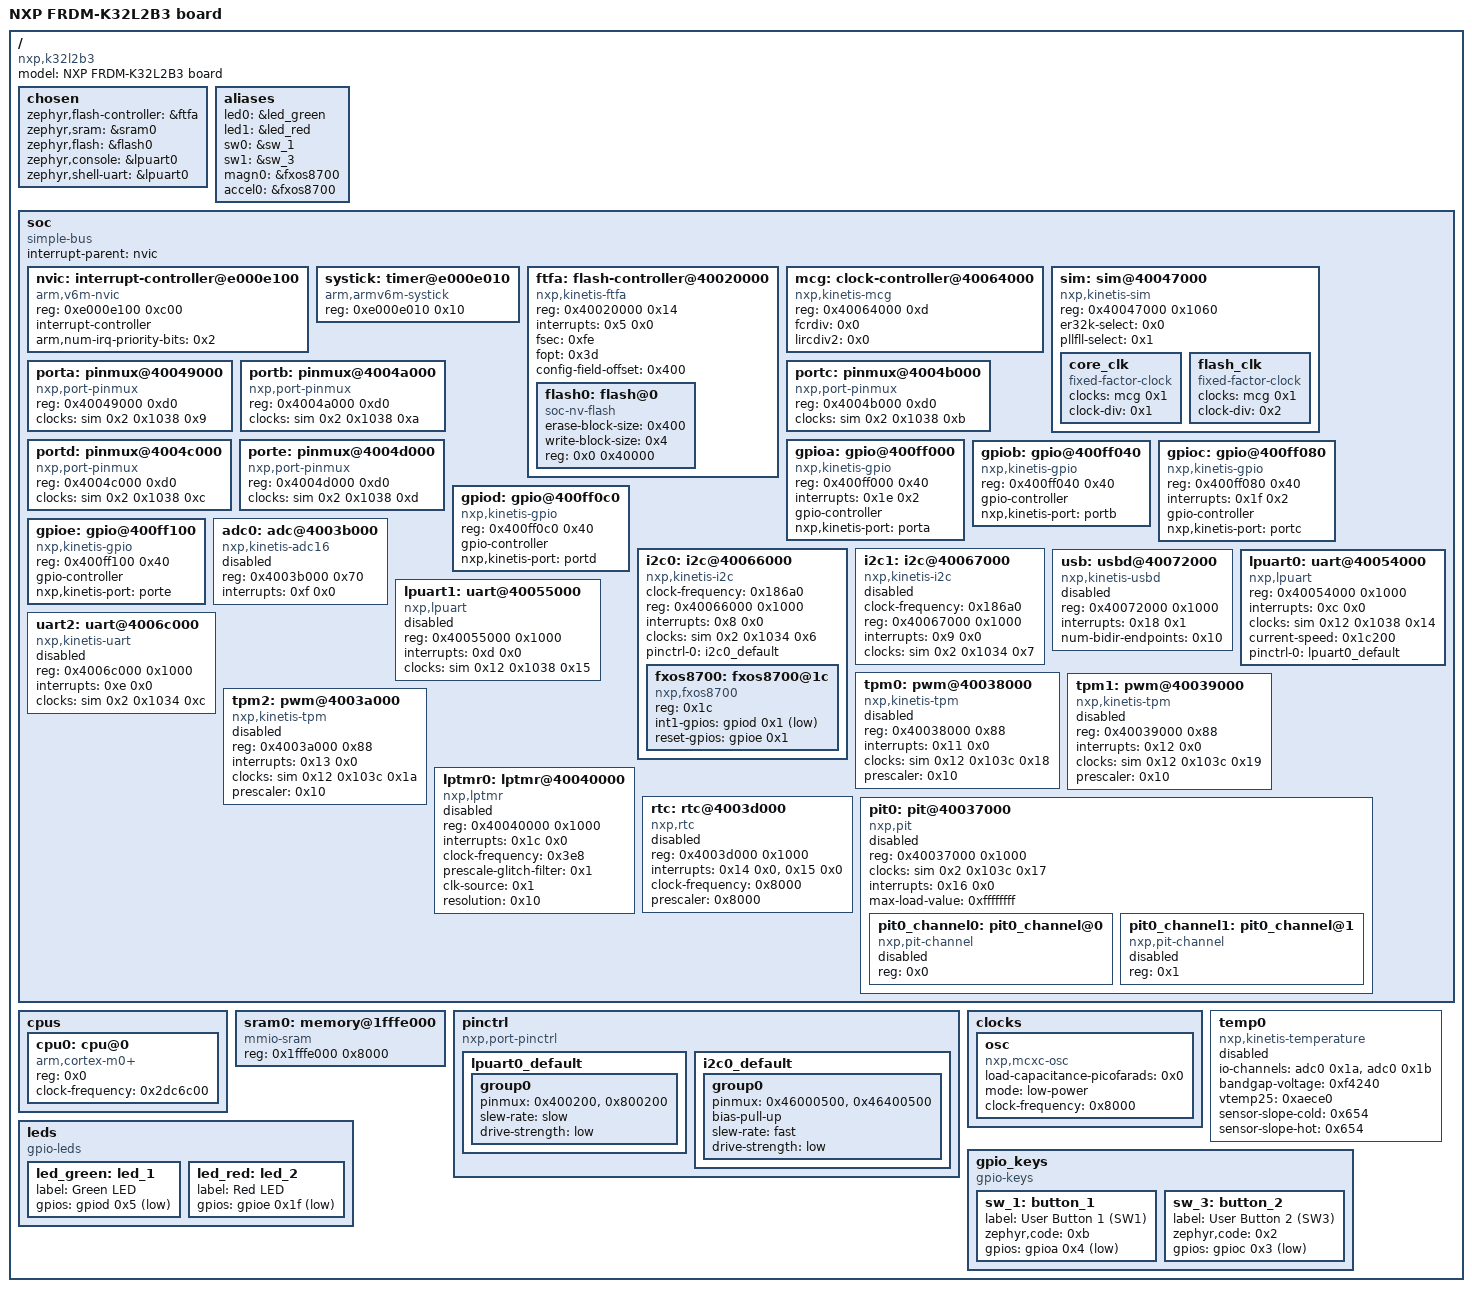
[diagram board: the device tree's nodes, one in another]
/dts-v1/;

/* node '/' defined in zephyr/dts/common/skeleton.dtsi:9 */
/ {
	#address-cells = < 0x1 >;         /* in zephyr/dts/common/skeleton.dtsi:10 */
	#size-cells = < 0x1 >;            /* in zephyr/dts/common/skeleton.dtsi:11 */
	model = "NXP FRDM-K32L2B3 board"; /* in zephyr/boards/nxp/frdm_k32l2b3/frdm_k32l2b3.dts:15 */
	compatible = "nxp,k32l2b3",
	             "nxp,k32lx";         /* in zephyr/boards/nxp/frdm_k32l2b3/frdm_k32l2b3.dts:16 */

	/* node '/chosen' defined in zephyr/dts/common/skeleton.dtsi:13 */
	chosen {
		zephyr,flash-controller = &ftfa; /* in zephyr/dts/arm/nxp/nxp_k32l2b3.dtsi:19 */
		zephyr,sram = &sram0;            /* in zephyr/boards/nxp/frdm_k32l2b3/frdm_k32l2b3.dts:28 */
		zephyr,flash = &flash0;          /* in zephyr/boards/nxp/frdm_k32l2b3/frdm_k32l2b3.dts:29 */
		zephyr,console = &lpuart0;       /* in zephyr/boards/nxp/frdm_k32l2b3/frdm_k32l2b3.dts:30 */
		zephyr,shell-uart = &lpuart0;    /* in zephyr/boards/nxp/frdm_k32l2b3/frdm_k32l2b3.dts:31 */
	};

	/* node '/aliases' defined in zephyr/dts/common/skeleton.dtsi:15 */
	aliases {
		led0 = &led_green;  /* in zephyr/boards/nxp/frdm_k32l2b3/frdm_k32l2b3.dts:19 */
		led1 = &led_red;    /* in zephyr/boards/nxp/frdm_k32l2b3/frdm_k32l2b3.dts:20 */
		sw0 = &sw_1;        /* in zephyr/boards/nxp/frdm_k32l2b3/frdm_k32l2b3.dts:21 */
		sw1 = &sw_3;        /* in zephyr/boards/nxp/frdm_k32l2b3/frdm_k32l2b3.dts:22 */
		magn0 = &fxos8700;  /* in zephyr/boards/nxp/frdm_k32l2b3/frdm_k32l2b3.dts:23 */
		accel0 = &fxos8700; /* in zephyr/boards/nxp/frdm_k32l2b3/frdm_k32l2b3.dts:24 */
	};

	/* node '/soc' defined in zephyr/dts/arm/armv6-m.dtsi:6 */
	soc {
		#address-cells = < 0x1 >;     /* in zephyr/dts/arm/armv6-m.dtsi:7 */
		#size-cells = < 0x1 >;        /* in zephyr/dts/arm/armv6-m.dtsi:8 */
		compatible = "simple-bus";    /* in zephyr/dts/arm/armv6-m.dtsi:9 */
		interrupt-parent = < &nvic >; /* in zephyr/dts/arm/armv6-m.dtsi:10 */
		ranges;                       /* in zephyr/dts/arm/armv6-m.dtsi:11 */

		/* node '/soc/interrupt-controller@e000e100' defined in zephyr/dts/arm/armv6-m.dtsi:13 */
		nvic: interrupt-controller@e000e100 {
			#address-cells = < 0x1 >;            /* in zephyr/dts/arm/armv6-m.dtsi:14 */
			compatible = "arm,v6m-nvic";         /* in zephyr/dts/arm/armv6-m.dtsi:15 */
			reg = < 0xe000e100 0xc00 >;          /* in zephyr/dts/arm/armv6-m.dtsi:16 */
			interrupt-controller;                /* in zephyr/dts/arm/armv6-m.dtsi:17 */
			#interrupt-cells = < 0x2 >;          /* in zephyr/dts/arm/armv6-m.dtsi:18 */
			arm,num-irq-priority-bits = < 0x2 >; /* in zephyr/dts/arm/nxp/nxp_k32l2b3.dtsi:328 */
			phandle = < 0x1 >;                   /* in zephyr/dts/arm/armv6-m.dtsi:10 */
		};

		/* node '/soc/timer@e000e010' defined in zephyr/dts/arm/armv6-m.dtsi:21 */
		systick: timer@e000e010 {
			compatible = "arm,armv6m-systick"; /* in zephyr/dts/arm/armv6-m.dtsi:22 */
			reg = < 0xe000e010 0x10 >;         /* in zephyr/dts/arm/armv6-m.dtsi:23 */
		};

		/* node '/soc/flash-controller@40020000' defined in zephyr/dts/arm/nxp/nxp_k32l2b3.dtsi:64 */
		ftfa: flash-controller@40020000 {
			compatible = "nxp,kinetis-ftfa"; /* in zephyr/dts/arm/nxp/nxp_k32l2b3.dtsi:65 */
			reg = < 0x40020000 0x14 >;       /* in zephyr/dts/arm/nxp/nxp_k32l2b3.dtsi:66 */
			interrupts = < 0x5 0x0 >;        /* in zephyr/dts/arm/nxp/nxp_k32l2b3.dtsi:67 */
			#address-cells = < 0x1 >;        /* in zephyr/dts/arm/nxp/nxp_k32l2b3.dtsi:69 */
			#size-cells = < 0x1 >;           /* in zephyr/dts/arm/nxp/nxp_k32l2b3.dtsi:70 */
			fsec = < 0xfe >;                 /* in zephyr/dts/arm/nxp/nxp_k32l2b3.dtsi:71 */
			fopt = < 0x3d >;                 /* in zephyr/dts/arm/nxp/nxp_k32l2b3.dtsi:72 */
			config-field-offset = < 0x400 >; /* in zephyr/dts/arm/nxp/nxp_k32l2b3.dtsi:73 */
			status = "okay";                 /* in zephyr/boards/nxp/frdm_k32l2b3/frdm_k32l2b3.dts:80 */

			/* node '/soc/flash-controller@40020000/flash@0' defined in zephyr/dts/arm/nxp/nxp_k32l2b3.dtsi:75 */
			flash0: flash@0 {
				compatible = "soc-nv-flash";  /* in zephyr/dts/arm/nxp/nxp_k32l2b3.dtsi:76 */
				erase-block-size = < 0x400 >; /* in zephyr/dts/arm/nxp/nxp_k32l2b3.dtsi:77 */
				write-block-size = < 0x4 >;   /* in zephyr/dts/arm/nxp/nxp_k32l2b3.dtsi:78 */
				reg = < 0x0 0x40000 >;        /* in zephyr/dts/arm/nxp/nxp_k32l2b3.dtsi:336 */
			};
		};

		/* node '/soc/clock-controller@40064000' defined in zephyr/dts/arm/nxp/nxp_k32l2b3.dtsi:82 */
		mcg: clock-controller@40064000 {
			compatible = "nxp,kinetis-mcg"; /* in zephyr/dts/arm/nxp/nxp_k32l2b3.dtsi:83 */
			reg = < 0x40064000 0xd >;       /* in zephyr/dts/arm/nxp/nxp_k32l2b3.dtsi:84 */
			fcrdiv = < 0x0 >;               /* in zephyr/dts/arm/nxp/nxp_k32l2b3.dtsi:85 */
			lircdiv2 = < 0x0 >;             /* in zephyr/dts/arm/nxp/nxp_k32l2b3.dtsi:86 */
			#clock-cells = < 0x1 >;         /* in zephyr/dts/arm/nxp/nxp_k32l2b3.dtsi:87 */
			phandle = < 0x2 >;              /* in zephyr/dts/arm/nxp/nxp_k32l2b3.dtsi:97 */
		};

		/* node '/soc/sim@40047000' defined in zephyr/dts/arm/nxp/nxp_k32l2b3.dtsi:90 */
		sim: sim@40047000 {
			compatible = "nxp,kinetis-sim"; /* in zephyr/dts/arm/nxp/nxp_k32l2b3.dtsi:91 */
			reg = < 0x40047000 0x1060 >;    /* in zephyr/dts/arm/nxp/nxp_k32l2b3.dtsi:92 */
			#clock-cells = < 0x3 >;         /* in zephyr/dts/arm/nxp/nxp_k32l2b3.dtsi:93 */
			er32k-select = < 0x0 >;         /* in zephyr/boards/nxp/frdm_k32l2b3/frdm_k32l2b3.dts:70 */
			pllfll-select = < 0x1 >;        /* in zephyr/boards/nxp/frdm_k32l2b3/frdm_k32l2b3.dts:71 */
			phandle = < 0x3 >;              /* in zephyr/dts/arm/nxp/nxp_k32l2b3.dtsi:113 */

			/* node '/soc/sim@40047000/core_clk' defined in zephyr/dts/arm/nxp/nxp_k32l2b3.dtsi:95 */
			core_clk {
				compatible = "fixed-factor-clock"; /* in zephyr/dts/arm/nxp/nxp_k32l2b3.dtsi:96 */
				clocks = < &mcg 0x1 >;             /* in zephyr/dts/arm/nxp/nxp_k32l2b3.dtsi:97 */
				clock-div = < 0x1 >;               /* in zephyr/dts/arm/nxp/nxp_k32l2b3.dtsi:98 */
				#clock-cells = < 0x0 >;            /* in zephyr/dts/arm/nxp/nxp_k32l2b3.dtsi:99 */
			};

			/* node '/soc/sim@40047000/flash_clk' defined in zephyr/dts/arm/nxp/nxp_k32l2b3.dtsi:102 */
			flash_clk {
				compatible = "fixed-factor-clock"; /* in zephyr/dts/arm/nxp/nxp_k32l2b3.dtsi:103 */
				clocks = < &mcg 0x1 >;             /* in zephyr/dts/arm/nxp/nxp_k32l2b3.dtsi:104 */
				clock-div = < 0x2 >;               /* in zephyr/dts/arm/nxp/nxp_k32l2b3.dtsi:105 */
				#clock-cells = < 0x0 >;            /* in zephyr/dts/arm/nxp/nxp_k32l2b3.dtsi:106 */
			};
		};

		/* node '/soc/pinmux@40049000' defined in zephyr/dts/arm/nxp/nxp_k32l2b3.dtsi:110 */
		porta: pinmux@40049000 {
			compatible = "nxp,port-pinmux";   /* in zephyr/dts/arm/nxp/nxp_k32l2b3.dtsi:111 */
			reg = < 0x40049000 0xd0 >;        /* in zephyr/dts/arm/nxp/nxp_k32l2b3.dtsi:112 */
			clocks = < &sim 0x2 0x1038 0x9 >; /* in zephyr/dts/arm/nxp/nxp_k32l2b3.dtsi:113 */
			phandle = < 0x4 >;                /* in zephyr/dts/arm/nxp/nxp_k32l2b3.dtsi:147 */
		};

		/* node '/soc/pinmux@4004a000' defined in zephyr/dts/arm/nxp/nxp_k32l2b3.dtsi:116 */
		portb: pinmux@4004a000 {
			compatible = "nxp,port-pinmux";   /* in zephyr/dts/arm/nxp/nxp_k32l2b3.dtsi:117 */
			reg = < 0x4004a000 0xd0 >;        /* in zephyr/dts/arm/nxp/nxp_k32l2b3.dtsi:118 */
			clocks = < &sim 0x2 0x1038 0xa >; /* in zephyr/dts/arm/nxp/nxp_k32l2b3.dtsi:119 */
			phandle = < 0x5 >;                /* in zephyr/dts/arm/nxp/nxp_k32l2b3.dtsi:156 */
		};

		/* node '/soc/pinmux@4004b000' defined in zephyr/dts/arm/nxp/nxp_k32l2b3.dtsi:122 */
		portc: pinmux@4004b000 {
			compatible = "nxp,port-pinmux";   /* in zephyr/dts/arm/nxp/nxp_k32l2b3.dtsi:123 */
			reg = < 0x4004b000 0xd0 >;        /* in zephyr/dts/arm/nxp/nxp_k32l2b3.dtsi:124 */
			clocks = < &sim 0x2 0x1038 0xb >; /* in zephyr/dts/arm/nxp/nxp_k32l2b3.dtsi:125 */
			phandle = < 0x6 >;                /* in zephyr/dts/arm/nxp/nxp_k32l2b3.dtsi:166 */
		};

		/* node '/soc/pinmux@4004c000' defined in zephyr/dts/arm/nxp/nxp_k32l2b3.dtsi:128 */
		portd: pinmux@4004c000 {
			compatible = "nxp,port-pinmux";   /* in zephyr/dts/arm/nxp/nxp_k32l2b3.dtsi:129 */
			reg = < 0x4004c000 0xd0 >;        /* in zephyr/dts/arm/nxp/nxp_k32l2b3.dtsi:130 */
			clocks = < &sim 0x2 0x1038 0xc >; /* in zephyr/dts/arm/nxp/nxp_k32l2b3.dtsi:131 */
			phandle = < 0x7 >;                /* in zephyr/dts/arm/nxp/nxp_k32l2b3.dtsi:175 */
		};

		/* node '/soc/pinmux@4004d000' defined in zephyr/dts/arm/nxp/nxp_k32l2b3.dtsi:134 */
		porte: pinmux@4004d000 {
			compatible = "nxp,port-pinmux";   /* in zephyr/dts/arm/nxp/nxp_k32l2b3.dtsi:135 */
			reg = < 0x4004d000 0xd0 >;        /* in zephyr/dts/arm/nxp/nxp_k32l2b3.dtsi:136 */
			clocks = < &sim 0x2 0x1038 0xd >; /* in zephyr/dts/arm/nxp/nxp_k32l2b3.dtsi:137 */
			phandle = < 0x8 >;                /* in zephyr/dts/arm/nxp/nxp_k32l2b3.dtsi:184 */
		};

		/* node '/soc/gpio@400ff000' defined in zephyr/dts/arm/nxp/nxp_k32l2b3.dtsi:140 */
		gpioa: gpio@400ff000 {
			compatible = "nxp,kinetis-gpio"; /* in zephyr/dts/arm/nxp/nxp_k32l2b3.dtsi:141 */
			reg = < 0x400ff000 0x40 >;       /* in zephyr/dts/arm/nxp/nxp_k32l2b3.dtsi:143 */
			interrupts = < 0x1e 0x2 >;       /* in zephyr/dts/arm/nxp/nxp_k32l2b3.dtsi:144 */
			gpio-controller;                 /* in zephyr/dts/arm/nxp/nxp_k32l2b3.dtsi:145 */
			#gpio-cells = < 0x2 >;           /* in zephyr/dts/arm/nxp/nxp_k32l2b3.dtsi:146 */
			nxp,kinetis-port = < &porta >;   /* in zephyr/dts/arm/nxp/nxp_k32l2b3.dtsi:147 */
			status = "okay";                 /* in zephyr/boards/nxp/frdm_k32l2b3/frdm_k32l2b3.dts:84 */
			phandle = < 0xe >;               /* in zephyr/boards/nxp/frdm_k32l2b3/frdm_k32l2b3.dts:54 */
		};

		/* node '/soc/gpio@400ff040' defined in zephyr/dts/arm/nxp/nxp_k32l2b3.dtsi:150 */
		gpiob: gpio@400ff040 {
			compatible = "nxp,kinetis-gpio"; /* in zephyr/dts/arm/nxp/nxp_k32l2b3.dtsi:151 */
			reg = < 0x400ff040 0x40 >;       /* in zephyr/dts/arm/nxp/nxp_k32l2b3.dtsi:153 */
			gpio-controller;                 /* in zephyr/dts/arm/nxp/nxp_k32l2b3.dtsi:154 */
			#gpio-cells = < 0x2 >;           /* in zephyr/dts/arm/nxp/nxp_k32l2b3.dtsi:155 */
			nxp,kinetis-port = < &portb >;   /* in zephyr/dts/arm/nxp/nxp_k32l2b3.dtsi:156 */
			status = "okay";                 /* in zephyr/boards/nxp/frdm_k32l2b3/frdm_k32l2b3.dts:88 */
		};

		/* node '/soc/gpio@400ff080' defined in zephyr/dts/arm/nxp/nxp_k32l2b3.dtsi:159 */
		gpioc: gpio@400ff080 {
			compatible = "nxp,kinetis-gpio"; /* in zephyr/dts/arm/nxp/nxp_k32l2b3.dtsi:160 */
			reg = < 0x400ff080 0x40 >;       /* in zephyr/dts/arm/nxp/nxp_k32l2b3.dtsi:162 */
			interrupts = < 0x1f 0x2 >;       /* in zephyr/dts/arm/nxp/nxp_k32l2b3.dtsi:163 */
			gpio-controller;                 /* in zephyr/dts/arm/nxp/nxp_k32l2b3.dtsi:164 */
			#gpio-cells = < 0x2 >;           /* in zephyr/dts/arm/nxp/nxp_k32l2b3.dtsi:165 */
			nxp,kinetis-port = < &portc >;   /* in zephyr/dts/arm/nxp/nxp_k32l2b3.dtsi:166 */
			status = "okay";                 /* in zephyr/boards/nxp/frdm_k32l2b3/frdm_k32l2b3.dts:92 */
			phandle = < 0xf >;               /* in zephyr/boards/nxp/frdm_k32l2b3/frdm_k32l2b3.dts:60 */
		};

		/* node '/soc/gpio@400ff0c0' defined in zephyr/dts/arm/nxp/nxp_k32l2b3.dtsi:169 */
		gpiod: gpio@400ff0c0 {
			compatible = "nxp,kinetis-gpio"; /* in zephyr/dts/arm/nxp/nxp_k32l2b3.dtsi:170 */
			reg = < 0x400ff0c0 0x40 >;       /* in zephyr/dts/arm/nxp/nxp_k32l2b3.dtsi:172 */
			gpio-controller;                 /* in zephyr/dts/arm/nxp/nxp_k32l2b3.dtsi:173 */
			#gpio-cells = < 0x2 >;           /* in zephyr/dts/arm/nxp/nxp_k32l2b3.dtsi:174 */
			nxp,kinetis-port = < &portd >;   /* in zephyr/dts/arm/nxp/nxp_k32l2b3.dtsi:175 */
			status = "okay";                 /* in zephyr/boards/nxp/frdm_k32l2b3/frdm_k32l2b3.dts:96 */
			phandle = < 0xa >;               /* in zephyr/boards/nxp/frdm_k32l2b3/frdm_k32l2b3.dts:118 */
		};

		/* node '/soc/gpio@400ff100' defined in zephyr/dts/arm/nxp/nxp_k32l2b3.dtsi:178 */
		gpioe: gpio@400ff100 {
			compatible = "nxp,kinetis-gpio"; /* in zephyr/dts/arm/nxp/nxp_k32l2b3.dtsi:179 */
			reg = < 0x400ff100 0x40 >;       /* in zephyr/dts/arm/nxp/nxp_k32l2b3.dtsi:181 */
			gpio-controller;                 /* in zephyr/dts/arm/nxp/nxp_k32l2b3.dtsi:182 */
			#gpio-cells = < 0x2 >;           /* in zephyr/dts/arm/nxp/nxp_k32l2b3.dtsi:183 */
			nxp,kinetis-port = < &porte >;   /* in zephyr/dts/arm/nxp/nxp_k32l2b3.dtsi:184 */
			status = "okay";                 /* in zephyr/boards/nxp/frdm_k32l2b3/frdm_k32l2b3.dts:100 */
			phandle = < 0xb >;               /* in zephyr/boards/nxp/frdm_k32l2b3/frdm_k32l2b3.dts:119 */
		};

		/* node '/soc/adc@4003b000' defined in zephyr/dts/arm/nxp/nxp_k32l2b3.dtsi:187 */
		adc0: adc@4003b000 {
			compatible = "nxp,kinetis-adc16"; /* in zephyr/dts/arm/nxp/nxp_k32l2b3.dtsi:188 */
			reg = < 0x4003b000 0x70 >;        /* in zephyr/dts/arm/nxp/nxp_k32l2b3.dtsi:189 */
			interrupts = < 0xf 0x0 >;         /* in zephyr/dts/arm/nxp/nxp_k32l2b3.dtsi:190 */
			status = "disabled";              /* in zephyr/dts/arm/nxp/nxp_k32l2b3.dtsi:191 */
			#io-channel-cells = < 0x1 >;      /* in zephyr/dts/arm/nxp/nxp_k32l2b3.dtsi:192 */
			phandle = < 0xd >;                /* in zephyr/dts/arm/nxp/nxp_k32l2b3.dtsi:54 */
		};

		/* node '/soc/i2c@40066000' defined in zephyr/dts/arm/nxp/nxp_k32l2b3.dtsi:195 */
		i2c0: i2c@40066000 {
			compatible = "nxp,kinetis-i2c";   /* in zephyr/dts/arm/nxp/nxp_k32l2b3.dtsi:196 */
			clock-frequency = < 0x186a0 >;    /* in zephyr/dts/arm/nxp/nxp_k32l2b3.dtsi:197 */
			#address-cells = < 0x1 >;         /* in zephyr/dts/arm/nxp/nxp_k32l2b3.dtsi:198 */
			#size-cells = < 0x0 >;            /* in zephyr/dts/arm/nxp/nxp_k32l2b3.dtsi:199 */
			reg = < 0x40066000 0x1000 >;      /* in zephyr/dts/arm/nxp/nxp_k32l2b3.dtsi:200 */
			interrupts = < 0x8 0x0 >;         /* in zephyr/dts/arm/nxp/nxp_k32l2b3.dtsi:201 */
			clocks = < &sim 0x2 0x1034 0x6 >; /* in zephyr/dts/arm/nxp/nxp_k32l2b3.dtsi:202 */
			status = "okay";                  /* in zephyr/boards/nxp/frdm_k32l2b3/frdm_k32l2b3.dts:111 */
			pinctrl-0 = < &i2c0_default >;    /* in zephyr/boards/nxp/frdm_k32l2b3/frdm_k32l2b3.dts:112 */
			pinctrl-names = "default";        /* in zephyr/boards/nxp/frdm_k32l2b3/frdm_k32l2b3.dts:113 */

			/* node '/soc/i2c@40066000/fxos8700@1c' defined in zephyr/boards/nxp/frdm_k32l2b3/frdm_k32l2b3.dts:115 */
			fxos8700: fxos8700@1c {
				compatible = "nxp,fxos8700";      /* in zephyr/boards/nxp/frdm_k32l2b3/frdm_k32l2b3.dts:116 */
				reg = < 0x1c >;                   /* in zephyr/boards/nxp/frdm_k32l2b3/frdm_k32l2b3.dts:117 */
				int1-gpios = < &gpiod 0x1 0x1 >;  /* in zephyr/boards/nxp/frdm_k32l2b3/frdm_k32l2b3.dts:118 */
				reset-gpios = < &gpioe 0x1 0x0 >; /* in zephyr/boards/nxp/frdm_k32l2b3/frdm_k32l2b3.dts:119 */
			};
		};

		/* node '/soc/i2c@40067000' defined in zephyr/dts/arm/nxp/nxp_k32l2b3.dtsi:206 */
		i2c1: i2c@40067000 {
			compatible = "nxp,kinetis-i2c";   /* in zephyr/dts/arm/nxp/nxp_k32l2b3.dtsi:207 */
			clock-frequency = < 0x186a0 >;    /* in zephyr/dts/arm/nxp/nxp_k32l2b3.dtsi:208 */
			#address-cells = < 0x1 >;         /* in zephyr/dts/arm/nxp/nxp_k32l2b3.dtsi:209 */
			#size-cells = < 0x0 >;            /* in zephyr/dts/arm/nxp/nxp_k32l2b3.dtsi:210 */
			reg = < 0x40067000 0x1000 >;      /* in zephyr/dts/arm/nxp/nxp_k32l2b3.dtsi:211 */
			interrupts = < 0x9 0x0 >;         /* in zephyr/dts/arm/nxp/nxp_k32l2b3.dtsi:212 */
			clocks = < &sim 0x2 0x1034 0x7 >; /* in zephyr/dts/arm/nxp/nxp_k32l2b3.dtsi:213 */
			status = "disabled";              /* in zephyr/dts/arm/nxp/nxp_k32l2b3.dtsi:214 */
		};

		/* node '/soc/usbd@40072000' defined in zephyr/dts/arm/nxp/nxp_k32l2b3.dtsi:217 */
		usb: usbd@40072000 {
			compatible = "nxp,kinetis-usbd"; /* in zephyr/dts/arm/nxp/nxp_k32l2b3.dtsi:218 */
			reg = < 0x40072000 0x1000 >;     /* in zephyr/dts/arm/nxp/nxp_k32l2b3.dtsi:219 */
			interrupts = < 0x18 0x1 >;       /* in zephyr/dts/arm/nxp/nxp_k32l2b3.dtsi:220 */
			interrupt-names = "usb";         /* in zephyr/dts/arm/nxp/nxp_k32l2b3.dtsi:221 */
			num-bidir-endpoints = < 0x10 >;  /* in zephyr/dts/arm/nxp/nxp_k32l2b3.dtsi:222 */
			status = "disabled";             /* in zephyr/dts/arm/nxp/nxp_k32l2b3.dtsi:223 */
		};

		/* node '/soc/uart@40054000' defined in zephyr/dts/arm/nxp/nxp_k32l2b3.dtsi:226 */
		lpuart0: uart@40054000 {
			compatible = "nxp,lpuart";          /* in zephyr/dts/arm/nxp/nxp_k32l2b3.dtsi:227 */
			reg = < 0x40054000 0x1000 >;        /* in zephyr/dts/arm/nxp/nxp_k32l2b3.dtsi:228 */
			interrupts = < 0xc 0x0 >;           /* in zephyr/dts/arm/nxp/nxp_k32l2b3.dtsi:229 */
			clocks = < &sim 0x12 0x1038 0x14 >; /* in zephyr/dts/arm/nxp/nxp_k32l2b3.dtsi:230 */
			status = "okay";                    /* in zephyr/boards/nxp/frdm_k32l2b3/frdm_k32l2b3.dts:104 */
			current-speed = < 0x1c200 >;        /* in zephyr/boards/nxp/frdm_k32l2b3/frdm_k32l2b3.dts:105 */
			pinctrl-0 = < &lpuart0_default >;   /* in zephyr/boards/nxp/frdm_k32l2b3/frdm_k32l2b3.dts:106 */
			pinctrl-names = "default";          /* in zephyr/boards/nxp/frdm_k32l2b3/frdm_k32l2b3.dts:107 */
		};

		/* node '/soc/uart@40055000' defined in zephyr/dts/arm/nxp/nxp_k32l2b3.dtsi:234 */
		lpuart1: uart@40055000 {
			compatible = "nxp,lpuart";          /* in zephyr/dts/arm/nxp/nxp_k32l2b3.dtsi:235 */
			reg = < 0x40055000 0x1000 >;        /* in zephyr/dts/arm/nxp/nxp_k32l2b3.dtsi:236 */
			interrupts = < 0xd 0x0 >;           /* in zephyr/dts/arm/nxp/nxp_k32l2b3.dtsi:237 */
			clocks = < &sim 0x12 0x1038 0x15 >; /* in zephyr/dts/arm/nxp/nxp_k32l2b3.dtsi:238 */
			status = "disabled";                /* in zephyr/dts/arm/nxp/nxp_k32l2b3.dtsi:239 */
		};

		/* node '/soc/uart@4006c000' defined in zephyr/dts/arm/nxp/nxp_k32l2b3.dtsi:242 */
		uart2: uart@4006c000 {
			compatible = "nxp,kinetis-uart";  /* in zephyr/dts/arm/nxp/nxp_k32l2b3.dtsi:243 */
			reg = < 0x4006c000 0x1000 >;      /* in zephyr/dts/arm/nxp/nxp_k32l2b3.dtsi:244 */
			interrupts = < 0xe 0x0 >;         /* in zephyr/dts/arm/nxp/nxp_k32l2b3.dtsi:245 */
			interrupt-names = "status";       /* in zephyr/dts/arm/nxp/nxp_k32l2b3.dtsi:246 */
			clocks = < &sim 0x2 0x1034 0xc >; /* in zephyr/dts/arm/nxp/nxp_k32l2b3.dtsi:247 */
			status = "disabled";              /* in zephyr/dts/arm/nxp/nxp_k32l2b3.dtsi:248 */
		};

		/* node '/soc/pwm@40038000' defined in zephyr/dts/arm/nxp/nxp_k32l2b3.dtsi:251 */
		tpm0: pwm@40038000 {
			compatible = "nxp,kinetis-tpm";     /* in zephyr/dts/arm/nxp/nxp_k32l2b3.dtsi:252 */
			reg = < 0x40038000 0x88 >;          /* in zephyr/dts/arm/nxp/nxp_k32l2b3.dtsi:253 */
			interrupts = < 0x11 0x0 >;          /* in zephyr/dts/arm/nxp/nxp_k32l2b3.dtsi:254 */
			clocks = < &sim 0x12 0x103c 0x18 >; /* in zephyr/dts/arm/nxp/nxp_k32l2b3.dtsi:255 */
			prescaler = < 0x10 >;               /* in zephyr/dts/arm/nxp/nxp_k32l2b3.dtsi:256 */
			status = "disabled";                /* in zephyr/dts/arm/nxp/nxp_k32l2b3.dtsi:257 */
			#pwm-cells = < 0x3 >;               /* in zephyr/dts/arm/nxp/nxp_k32l2b3.dtsi:258 */
		};

		/* node '/soc/pwm@40039000' defined in zephyr/dts/arm/nxp/nxp_k32l2b3.dtsi:261 */
		tpm1: pwm@40039000 {
			compatible = "nxp,kinetis-tpm";     /* in zephyr/dts/arm/nxp/nxp_k32l2b3.dtsi:262 */
			reg = < 0x40039000 0x88 >;          /* in zephyr/dts/arm/nxp/nxp_k32l2b3.dtsi:263 */
			interrupts = < 0x12 0x0 >;          /* in zephyr/dts/arm/nxp/nxp_k32l2b3.dtsi:264 */
			clocks = < &sim 0x12 0x103c 0x19 >; /* in zephyr/dts/arm/nxp/nxp_k32l2b3.dtsi:265 */
			prescaler = < 0x10 >;               /* in zephyr/dts/arm/nxp/nxp_k32l2b3.dtsi:266 */
			status = "disabled";                /* in zephyr/dts/arm/nxp/nxp_k32l2b3.dtsi:267 */
			#pwm-cells = < 0x3 >;               /* in zephyr/dts/arm/nxp/nxp_k32l2b3.dtsi:268 */
		};

		/* node '/soc/pwm@4003a000' defined in zephyr/dts/arm/nxp/nxp_k32l2b3.dtsi:271 */
		tpm2: pwm@4003a000 {
			compatible = "nxp,kinetis-tpm";     /* in zephyr/dts/arm/nxp/nxp_k32l2b3.dtsi:272 */
			reg = < 0x4003a000 0x88 >;          /* in zephyr/dts/arm/nxp/nxp_k32l2b3.dtsi:273 */
			interrupts = < 0x13 0x0 >;          /* in zephyr/dts/arm/nxp/nxp_k32l2b3.dtsi:274 */
			clocks = < &sim 0x12 0x103c 0x1a >; /* in zephyr/dts/arm/nxp/nxp_k32l2b3.dtsi:275 */
			prescaler = < 0x10 >;               /* in zephyr/dts/arm/nxp/nxp_k32l2b3.dtsi:276 */
			status = "disabled";                /* in zephyr/dts/arm/nxp/nxp_k32l2b3.dtsi:277 */
			#pwm-cells = < 0x3 >;               /* in zephyr/dts/arm/nxp/nxp_k32l2b3.dtsi:278 */
		};

		/* node '/soc/lptmr@40040000' defined in zephyr/dts/arm/nxp/nxp_k32l2b3.dtsi:281 */
		lptmr0: lptmr@40040000 {
			compatible = "nxp,lptmr";         /* in zephyr/dts/arm/nxp/nxp_k32l2b3.dtsi:282 */
			reg = < 0x40040000 0x1000 >;      /* in zephyr/dts/arm/nxp/nxp_k32l2b3.dtsi:283 */
			interrupts = < 0x1c 0x0 >;        /* in zephyr/dts/arm/nxp/nxp_k32l2b3.dtsi:284 */
			clock-frequency = < 0x3e8 >;      /* in zephyr/dts/arm/nxp/nxp_k32l2b3.dtsi:285 */
			prescale-glitch-filter = < 0x1 >; /* in zephyr/dts/arm/nxp/nxp_k32l2b3.dtsi:286 */
			clk-source = < 0x1 >;             /* in zephyr/dts/arm/nxp/nxp_k32l2b3.dtsi:287 */
			resolution = < 0x10 >;            /* in zephyr/dts/arm/nxp/nxp_k32l2b3.dtsi:288 */
			status = "disabled";              /* in zephyr/dts/arm/nxp/nxp_k32l2b3.dtsi:289 */
		};

		/* node '/soc/rtc@4003d000' defined in zephyr/dts/arm/nxp/nxp_k32l2b3.dtsi:292 */
		rtc: rtc@4003d000 {
			compatible = "nxp,rtc";       /* in zephyr/dts/arm/nxp/nxp_k32l2b3.dtsi:293 */
			reg = < 0x4003d000 0x1000 >;  /* in zephyr/dts/arm/nxp/nxp_k32l2b3.dtsi:294 */
			interrupts = < 0x14 0x0 >,
			             < 0x15 0x0 >;    /* in zephyr/dts/arm/nxp/nxp_k32l2b3.dtsi:295 */
			interrupt-names = "alarm",
			                  "seconds";  /* in zephyr/dts/arm/nxp/nxp_k32l2b3.dtsi:296 */
			clock-frequency = < 0x8000 >; /* in zephyr/dts/arm/nxp/nxp_k32l2b3.dtsi:297 */
			prescaler = < 0x8000 >;       /* in zephyr/dts/arm/nxp/nxp_k32l2b3.dtsi:298 */
			status = "disabled";          /* in zephyr/dts/arm/nxp/nxp_k32l2b3.dtsi:299 */
		};

		/* node '/soc/pit@40037000' defined in zephyr/dts/arm/nxp/nxp_k32l2b3.dtsi:302 */
		pit0: pit@40037000 {
			compatible = "nxp,pit";            /* in zephyr/dts/arm/nxp/nxp_k32l2b3.dtsi:303 */
			reg = < 0x40037000 0x1000 >;       /* in zephyr/dts/arm/nxp/nxp_k32l2b3.dtsi:304 */
			clocks = < &sim 0x2 0x103c 0x17 >; /* in zephyr/dts/arm/nxp/nxp_k32l2b3.dtsi:305 */
			interrupts = < 0x16 0x0 >;         /* in zephyr/dts/arm/nxp/nxp_k32l2b3.dtsi:306 */
			max-load-value = < 0xffffffff >;   /* in zephyr/dts/arm/nxp/nxp_k32l2b3.dtsi:307 */
			status = "disabled";               /* in zephyr/dts/arm/nxp/nxp_k32l2b3.dtsi:308 */
			#address-cells = < 0x1 >;          /* in zephyr/dts/arm/nxp/nxp_k32l2b3.dtsi:309 */
			#size-cells = < 0x0 >;             /* in zephyr/dts/arm/nxp/nxp_k32l2b3.dtsi:310 */

			/* node '/soc/pit@40037000/pit0_channel@0' defined in zephyr/dts/arm/nxp/nxp_k32l2b3.dtsi:312 */
			pit0_channel0: pit0_channel@0 {
				compatible = "nxp,pit-channel"; /* in zephyr/dts/arm/nxp/nxp_k32l2b3.dtsi:313 */
				reg = < 0x0 >;                  /* in zephyr/dts/arm/nxp/nxp_k32l2b3.dtsi:314 */
				status = "disabled";            /* in zephyr/dts/arm/nxp/nxp_k32l2b3.dtsi:315 */
			};

			/* node '/soc/pit@40037000/pit0_channel@1' defined in zephyr/dts/arm/nxp/nxp_k32l2b3.dtsi:318 */
			pit0_channel1: pit0_channel@1 {
				compatible = "nxp,pit-channel"; /* in zephyr/dts/arm/nxp/nxp_k32l2b3.dtsi:319 */
				reg = < 0x1 >;                  /* in zephyr/dts/arm/nxp/nxp_k32l2b3.dtsi:320 */
				status = "disabled";            /* in zephyr/dts/arm/nxp/nxp_k32l2b3.dtsi:321 */
			};
		};
	};

	/* node '/cpus' defined in zephyr/dts/arm/nxp/nxp_k32l2b3.dtsi:22 */
	cpus {
		#address-cells = < 0x1 >; /* in zephyr/dts/arm/nxp/nxp_k32l2b3.dtsi:23 */
		#size-cells = < 0x0 >;    /* in zephyr/dts/arm/nxp/nxp_k32l2b3.dtsi:24 */

		/* node '/cpus/cpu@0' defined in zephyr/dts/arm/nxp/nxp_k32l2b3.dtsi:26 */
		cpu0: cpu@0 {
			device_type = "cpu";             /* in zephyr/dts/arm/nxp/nxp_k32l2b3.dtsi:27 */
			compatible = "arm,cortex-m0+";   /* in zephyr/dts/arm/nxp/nxp_k32l2b3.dtsi:28 */
			reg = < 0x0 >;                   /* in zephyr/dts/arm/nxp/nxp_k32l2b3.dtsi:29 */
			clock-frequency = < 0x2dc6c00 >; /* in zephyr/boards/nxp/frdm_k32l2b3/frdm_k32l2b3.dts:66 */
		};
	};

	/* node '/memory@1fffe000' defined in zephyr/dts/arm/nxp/nxp_k32l2b3.dtsi:33 */
	sram0: memory@1fffe000 {
		compatible = "mmio-sram";    /* in zephyr/dts/arm/nxp/nxp_k32l2b3.dtsi:34 */
		reg = < 0x1fffe000 0x8000 >; /* in zephyr/dts/arm/nxp/nxp_k32l2b3.dtsi:332 */
	};

	/* node '/pinctrl' defined in zephyr/dts/arm/nxp/nxp_k32l2b3.dtsi:38 */
	pinctrl: pinctrl {
		compatible = "nxp,port-pinctrl"; /* in zephyr/dts/arm/nxp/nxp_k32l2b3.dtsi:39 */
		status = "okay";                 /* in zephyr/dts/arm/nxp/nxp_k32l2b3.dtsi:40 */

		/* node '/pinctrl/lpuart0_default' defined in zephyr/boards/nxp/frdm_k32l2b3/frdm_k32l2b3-pinctrl.dtsi:10 */
		lpuart0_default: lpuart0_default {
			phandle = < 0xc >; /* in zephyr/boards/nxp/frdm_k32l2b3/frdm_k32l2b3.dts:106 */

			/* node '/pinctrl/lpuart0_default/group0' defined in zephyr/boards/nxp/frdm_k32l2b3/frdm_k32l2b3-pinctrl.dtsi:11 */
			group0 {
				pinmux = < 0x400200 >,
				         < 0x800200 >;  /* in zephyr/boards/nxp/frdm_k32l2b3/frdm_k32l2b3-pinctrl.dtsi:12 */
				slew-rate = "slow";     /* in zephyr/boards/nxp/frdm_k32l2b3/frdm_k32l2b3-pinctrl.dtsi:14 */
				drive-strength = "low"; /* in zephyr/boards/nxp/frdm_k32l2b3/frdm_k32l2b3-pinctrl.dtsi:15 */
			};
		};

		/* node '/pinctrl/i2c0_default' defined in zephyr/boards/nxp/frdm_k32l2b3/frdm_k32l2b3-pinctrl.dtsi:19 */
		i2c0_default: i2c0_default {
			phandle = < 0x9 >; /* in zephyr/boards/nxp/frdm_k32l2b3/frdm_k32l2b3.dts:112 */

			/* node '/pinctrl/i2c0_default/group0' defined in zephyr/boards/nxp/frdm_k32l2b3/frdm_k32l2b3-pinctrl.dtsi:20 */
			group0 {
				pinmux = < 0x46000500 >,
				         < 0x46400500 >; /* in zephyr/boards/nxp/frdm_k32l2b3/frdm_k32l2b3-pinctrl.dtsi:21 */
				bias-pull-up;            /* in zephyr/boards/nxp/frdm_k32l2b3/frdm_k32l2b3-pinctrl.dtsi:23 */
				slew-rate = "fast";      /* in zephyr/boards/nxp/frdm_k32l2b3/frdm_k32l2b3-pinctrl.dtsi:24 */
				drive-strength = "low";  /* in zephyr/boards/nxp/frdm_k32l2b3/frdm_k32l2b3-pinctrl.dtsi:25 */
			};
		};
	};

	/* node '/clocks' defined in zephyr/dts/arm/nxp/nxp_k32l2b3.dtsi:43 */
	clocks {

		/* node '/clocks/osc' defined in zephyr/dts/arm/nxp/nxp_k32l2b3.dtsi:44 */
		osc: osc {
			compatible = "nxp,mcxc-osc";           /* in zephyr/dts/arm/nxp/nxp_k32l2b3.dtsi:45 */
			#clock-cells = < 0x0 >;                /* in zephyr/dts/arm/nxp/nxp_k32l2b3.dtsi:46 */
			load-capacitance-picofarads = < 0x0 >; /* in zephyr/dts/arm/nxp/nxp_k32l2b3.dtsi:47 */
			mode = "low-power";                    /* in zephyr/boards/nxp/frdm_k32l2b3/frdm_k32l2b3.dts:75 */
			clock-frequency = < 0x8000 >;          /* in zephyr/boards/nxp/frdm_k32l2b3/frdm_k32l2b3.dts:76 */
		};
	};

	/* node '/temp0' defined in zephyr/dts/arm/nxp/nxp_k32l2b3.dtsi:52 */
	temp0: temp0 {
		compatible = "nxp,kinetis-temperature"; /* in zephyr/dts/arm/nxp/nxp_k32l2b3.dtsi:53 */
		io-channels = < &adc0 0x1a >,
		              < &adc0 0x1b >;           /* in zephyr/dts/arm/nxp/nxp_k32l2b3.dtsi:54 */
		io-channel-names = "SENSOR",
		                   "BANDGAP";           /* in zephyr/dts/arm/nxp/nxp_k32l2b3.dtsi:55 */
		bandgap-voltage = < 0xf4240 >;          /* in zephyr/dts/arm/nxp/nxp_k32l2b3.dtsi:56 */
		vtemp25 = < 0xaece0 >;                  /* in zephyr/dts/arm/nxp/nxp_k32l2b3.dtsi:57 */
		sensor-slope-cold = < 0x654 >;          /* in zephyr/dts/arm/nxp/nxp_k32l2b3.dtsi:58 */
		sensor-slope-hot = < 0x654 >;           /* in zephyr/dts/arm/nxp/nxp_k32l2b3.dtsi:59 */
		status = "disabled";                    /* in zephyr/dts/arm/nxp/nxp_k32l2b3.dtsi:60 */
	};

	/* node '/leds' defined in zephyr/boards/nxp/frdm_k32l2b3/frdm_k32l2b3.dts:34 */
	leds {
		compatible = "gpio-leds"; /* in zephyr/boards/nxp/frdm_k32l2b3/frdm_k32l2b3.dts:35 */

		/* node '/leds/led_1' defined in zephyr/boards/nxp/frdm_k32l2b3/frdm_k32l2b3.dts:37 */
		led_green: led_1 {
			label = "Green LED";        /* in zephyr/boards/nxp/frdm_k32l2b3/frdm_k32l2b3.dts:38 */
			gpios = < &gpiod 0x5 0x1 >; /* in zephyr/boards/nxp/frdm_k32l2b3/frdm_k32l2b3.dts:39 */
		};

		/* node '/leds/led_2' defined in zephyr/boards/nxp/frdm_k32l2b3/frdm_k32l2b3.dts:42 */
		led_red: led_2 {
			label = "Red LED";           /* in zephyr/boards/nxp/frdm_k32l2b3/frdm_k32l2b3.dts:43 */
			gpios = < &gpioe 0x1f 0x1 >; /* in zephyr/boards/nxp/frdm_k32l2b3/frdm_k32l2b3.dts:44 */
		};
	};

	/* node '/gpio_keys' defined in zephyr/boards/nxp/frdm_k32l2b3/frdm_k32l2b3.dts:48 */
	gpio_keys {
		compatible = "gpio-keys"; /* in zephyr/boards/nxp/frdm_k32l2b3/frdm_k32l2b3.dts:49 */

		/* node '/gpio_keys/button_1' defined in zephyr/boards/nxp/frdm_k32l2b3/frdm_k32l2b3.dts:51 */
		sw_1: button_1 {
			label = "User Button 1 (SW1)"; /* in zephyr/boards/nxp/frdm_k32l2b3/frdm_k32l2b3.dts:52 */
			zephyr,code = < 0xb >;         /* in zephyr/boards/nxp/frdm_k32l2b3/frdm_k32l2b3.dts:53 */
			gpios = < &gpioa 0x4 0x1 >;    /* in zephyr/boards/nxp/frdm_k32l2b3/frdm_k32l2b3.dts:54 */
		};

		/* node '/gpio_keys/button_2' defined in zephyr/boards/nxp/frdm_k32l2b3/frdm_k32l2b3.dts:57 */
		sw_3: button_2 {
			label = "User Button 2 (SW3)"; /* in zephyr/boards/nxp/frdm_k32l2b3/frdm_k32l2b3.dts:58 */
			zephyr,code = < 0x2 >;         /* in zephyr/boards/nxp/frdm_k32l2b3/frdm_k32l2b3.dts:59 */
			gpios = < &gpioc 0x3 0x1 >;    /* in zephyr/boards/nxp/frdm_k32l2b3/frdm_k32l2b3.dts:60 */
		};
	};
};
